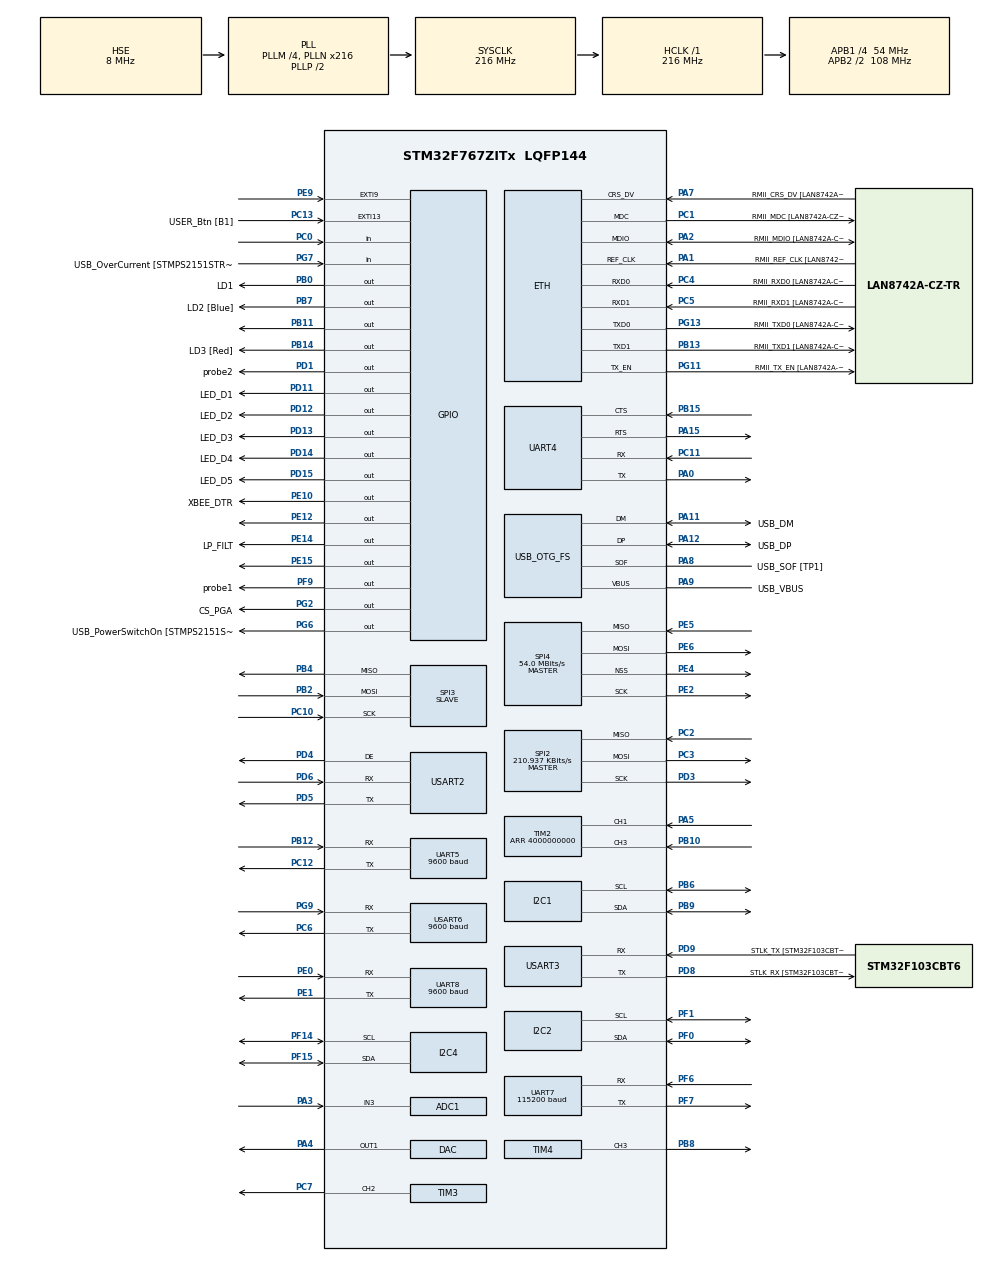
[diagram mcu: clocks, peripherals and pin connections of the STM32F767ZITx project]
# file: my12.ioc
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ADC1.Channel-6\#ChannelRegularConversion=ADC_CHANNEL_3
ADC1.ClockPrescaler=ADC_CLOCK_SYNC_PCLK_DIV4
ADC1.ContinuousConvMode=ENABLE
ADC1.DMAAccessMode=ADC_DMAACCESSMODE_2
ADC1.DMAContinuousRequests=ENABLE
ADC1.DataAlign=ADC_DATAALIGN_RIGHT
ADC1.DiscontinuousConvMode=DISABLE
ADC1.EOCSelection=ADC_EOC_SEQ_CONV
ADC1.EnableAnalogWatchDog=false
ADC1.ExternalTrigConv=ADC_SOFTWARE_START
ADC1.ExternalTrigConvEdge=ADC_EXTERNALTRIGCONVEDGE_NONE
ADC1.InjNumberOfConversion=0
ADC1.Mode=ADC_TRIPLEMODE_INTERL
ADC1.NbrOfConversion=1
ADC1.NbrOfConversionFlag=1
ADC1.Rank-6\#ChannelRegularConversion=1
ADC1.Resolution=ADC_RESOLUTION_12B
ADC1.SamplingTime-6\#ChannelRegularConversion=ADC_SAMPLETIME_3CYCLES
ADC1.ScanConvMode=ADC_SCAN_DISABLE
ADC1.TwoSamplingDelay=ADC_TWOSAMPLINGDELAY_5CYCLES
ADC1.master=1
ADC2.Channel-22\#ChannelRegularConversion=ADC_CHANNEL_3
ADC2.Channel-26\#ChannelRegularConversion=ADC_CHANNEL_3
ADC2.ContinuousConvMode=ENABLE
ADC2.DMAAccessMode=ADC_DMAACCESSMODE_2
ADC2.DMAContinuousRequests=DISABLE
ADC2.DataAlign=ADC_DATAALIGN_RIGHT
ADC2.DiscontinuousConvMode=DISABLE
ADC2.EOCSelection=ADC_EOC_SEQ_CONV
ADC2.EnableAnalogWatchDog=false
ADC2.InjNumberOfConversion=0
ADC2.Mode=ADC_TRIPLEMODE_INTERL
ADC2.NbrOfConversion=1
ADC2.NbrOfConversionFlag=1
ADC2.Rank-22\#ChannelRegularConversion=1
ADC2.Rank-26\#ChannelRegularConversion=1
ADC2.Resolution=ADC_RESOLUTION_12B
ADC2.SamplingTime-22\#ChannelRegularConversion=ADC_SAMPLETIME_3CYCLES
ADC2.SamplingTime-26\#ChannelRegularConversion=ADC_SAMPLETIME_3CYCLES
ADC2.ScanConvMode=ADC_SCAN_DISABLE
ADC3.Channel-14\#ChannelRegularConversion=ADC_CHANNEL_3
ADC3.ContinuousConvMode=ENABLE
ADC3.DMAAccessMode=ADC_DMAACCESSMODE_2
ADC3.DMAContinuousRequests=DISABLE
ADC3.DataAlign=ADC_DATAALIGN_RIGHT
ADC3.DiscontinuousConvMode=DISABLE
ADC3.EOCSelection=ADC_EOC_SEQ_CONV
ADC3.EnableAnalogWatchDog=false
ADC3.InjNumberOfConversion=0
ADC3.Mode=ADC_TRIPLEMODE_INTERL
ADC3.NbrOfConversion=1
ADC3.NbrOfConversionFlag=1
ADC3.Rank-14\#ChannelRegularConversion=1
ADC3.Resolution=ADC_RESOLUTION_12B
ADC3.SamplingTime-14\#ChannelRegularConversion=ADC_SAMPLETIME_3CYCLES
ADC3.ScanConvMode=ADC_SCAN_DISABLE
CORTEX_M7.CPU_DCache=Disabled
CORTEX_M7.CPU_ICache=Enabled
CORTEX_M7.PREFETCH_ENABLE=1
DAC.DAC_Trigger=DAC_TRIGGER_T7_TRGO
Dma.ADC1.2.Direction=DMA_PERIPH_TO_MEMORY
Dma.ADC1.2.FIFOMode=DMA_FIFOMODE_ENABLE
Dma.ADC1.2.FIFOThreshold=DMA_FIFO_THRESHOLD_FULL
Dma.ADC1.2.Instance=DMA2_Stream4
Dma.ADC1.2.MemBurst=DMA_MBURST_INC4
Dma.ADC1.2.MemDataAlignment=DMA_MDATAALIGN_WORD
Dma.ADC1.2.MemInc=DMA_MINC_ENABLE
Dma.ADC1.2.Mode=DMA_CIRCULAR
Dma.ADC1.2.PeriphBurst=DMA_PBURST_SINGLE
Dma.ADC1.2.PeriphDataAlignment=DMA_PDATAALIGN_HALFWORD
Dma.ADC1.2.PeriphInc=DMA_PINC_DISABLE
Dma.ADC1.2.Priority=DMA_PRIORITY_HIGH
Dma.DAC1.0.Direction=DMA_MEMORY_TO_PERIPH
Dma.DAC1.0.FIFOMode=DMA_FIFOMODE_ENABLE
Dma.DAC1.0.FIFOThreshold=DMA_FIFO_THRESHOLD_3QUARTERSFULL
Dma.DAC1.0.Instance=DMA1_Stream5
Dma.DAC1.0.MemBurst=DMA_MBURST_INC4
Dma.DAC1.0.MemDataAlignment=DMA_MDATAALIGN_BYTE
Dma.DAC1.0.MemInc=DMA_MINC_ENABLE
Dma.DAC1.0.Mode=DMA_NORMAL
Dma.DAC1.0.PeriphBurst=DMA_PBURST_SINGLE
Dma.DAC1.0.PeriphDataAlignment=DMA_PDATAALIGN_BYTE
Dma.DAC1.0.PeriphInc=DMA_PINC_DISABLE
Dma.DAC1.0.Priority=DMA_PRIORITY_LOW
Dma.Request0=DAC1
Dma.Request1=USART6_RX
Dma.Request2=ADC1
Dma.Request3=TIM2_UP/CH3
Dma.Request4=UART5_RX
Dma.Request5=UART5_TX
Dma.Request6=UART8_RX
Dma.Request7=USART6_TX
Dma.TIM2_UP/CH3.3.Direction=DMA_PERIPH_TO_MEMORY
Dma.TIM2_UP/CH3.3.FIFOMode=DMA_FIFOMODE_DISABLE
Dma.TIM2_UP/CH3.3.Instance=DMA1_Stream1
Dma.TIM2_UP/CH3.3.MemDataAlignment=DMA_MDATAALIGN_WORD
Dma.TIM2_UP/CH3.3.MemInc=DMA_MINC_ENABLE
Dma.TIM2_UP/CH3.3.Mode=DMA_CIRCULAR
Dma.TIM2_UP/CH3.3.PeriphDataAlignment=DMA_PDATAALIGN_WORD
Dma.TIM2_UP/CH3.3.PeriphInc=DMA_PINC_DISABLE
Dma.TIM2_UP/CH3.3.Priority=DMA_PRIORITY_LOW
Dma.UART5_RX.4.Direction=DMA_PERIPH_TO_MEMORY
Dma.UART5_RX.4.FIFOMode=DMA_FIFOMODE_DISABLE
Dma.UART5_RX.4.Instance=DMA1_Stream0
Dma.UART5_RX.4.MemDataAlignment=DMA_MDATAALIGN_BYTE
Dma.UART5_RX.4.MemInc=DMA_MINC_ENABLE
Dma.UART5_RX.4.Mode=DMA_CIRCULAR
Dma.UART5_RX.4.PeriphDataAlignment=DMA_PDATAALIGN_BYTE
Dma.UART5_RX.4.PeriphInc=DMA_PINC_DISABLE
Dma.UART5_RX.4.Priority=DMA_PRIORITY_LOW
Dma.UART5_TX.5.Direction=DMA_MEMORY_TO_PERIPH
Dma.UART5_TX.5.FIFOMode=DMA_FIFOMODE_DISABLE
Dma.UART5_TX.5.Instance=DMA1_Stream7
Dma.UART5_TX.5.MemDataAlignment=DMA_MDATAALIGN_BYTE
Dma.UART5_TX.5.MemInc=DMA_MINC_ENABLE
Dma.UART5_TX.5.Mode=DMA_NORMAL
Dma.UART5_TX.5.PeriphDataAlignment=DMA_PDATAALIGN_BYTE
Dma.UART5_TX.5.PeriphInc=DMA_PINC_DISABLE
Dma.UART5_TX.5.Priority=DMA_PRIORITY_LOW
Dma.UART8_RX.6.Direction=DMA_PERIPH_TO_MEMORY
Dma.UART8_RX.6.FIFOMode=DMA_FIFOMODE_DISABLE
Dma.UART8_RX.6.Instance=DMA1_Stream6
Dma.UART8_RX.6.MemDataAlignment=DMA_MDATAALIGN_BYTE
Dma.UART8_RX.6.MemInc=DMA_MINC_ENABLE
Dma.UART8_RX.6.Mode=DMA_CIRCULAR
Dma.UART8_RX.6.PeriphDataAlignment=DMA_PDATAALIGN_BYTE
Dma.UART8_RX.6.PeriphInc=DMA_PINC_DISABLE
Dma.UART8_RX.6.Priority=DMA_PRIORITY_MEDIUM
Dma.USART6_RX.1.Direction=DMA_PERIPH_TO_MEMORY
Dma.USART6_RX.1.FIFOMode=DMA_FIFOMODE_DISABLE
Dma.USART6_RX.1.Instance=DMA2_Stream1
Dma.USART6_RX.1.MemDataAlignment=DMA_MDATAALIGN_BYTE
Dma.USART6_RX.1.MemInc=DMA_MINC_ENABLE
Dma.USART6_RX.1.Mode=DMA_CIRCULAR
Dma.USART6_RX.1.PeriphDataAlignment=DMA_PDATAALIGN_BYTE
Dma.USART6_RX.1.PeriphInc=DMA_PINC_DISABLE
Dma.USART6_RX.1.Priority=DMA_PRIORITY_MEDIUM
Dma.USART6_TX.7.Direction=DMA_MEMORY_TO_PERIPH
Dma.USART6_TX.7.FIFOMode=DMA_FIFOMODE_ENABLE
Dma.USART6_TX.7.FIFOThreshold=DMA_FIFO_THRESHOLD_FULL
Dma.USART6_TX.7.Instance=DMA2_Stream6
Dma.USART6_TX.7.MemBurst=DMA_MBURST_INC4
Dma.USART6_TX.7.MemDataAlignment=DMA_MDATAALIGN_BYTE
Dma.USART6_TX.7.MemInc=DMA_MINC_ENABLE
Dma.USART6_TX.7.Mode=DMA_NORMAL
Dma.USART6_TX.7.PeriphBurst=DMA_PBURST_SINGLE
Dma.USART6_TX.7.PeriphDataAlignment=DMA_PDATAALIGN_BYTE
Dma.USART6_TX.7.PeriphInc=DMA_PINC_DISABLE
Dma.USART6_TX.7.Priority=DMA_PRIORITY_MEDIUM
ETH.ChecksumMode=ETH_CHECKSUM_BY_SOFTWARE
ETH.MACAddr=00\:80\:E1\:00\:AA\:02
ETH.MediaInterface=ETH_MEDIA_INTERFACE_RMII
ETH.PhyAddress=0
FREERTOS.BinarySemaphores01=ssicontent,Dynamic,NULL
FREERTOS.INCLUDE_vTaskCleanUpResources=1
FREERTOS.INCLUDE_vTaskDelayUntil=1
FREERTOS.INCLUDE_xQueueGetMutexHolder=1
FREERTOS.INCLUDE_xSemaphoreGetMutexHolder=1
FREERTOS.INCLUDE_xTimerPendFunctionCall=1
FREERTOS.Mutexes01=myMutex01,Dynamic,NULL
FREERTOS.Queues01=myQueue01,256,uint16_t,0,Dynamic,NULL,NULL
FREERTOS.Tasks01=defaultTask,0,2048,StartDefaultTask,Default,NULL,Dynamic,NULL,NULL;LPTask,-2,2048,StarLPTask,Default,NULL,Dynamic,NULL,NULL
FREERTOS.Timers01=myTimer01,Callback01,osTimerPeriodic,Default,NULL,Dynamic,NULL
FREERTOS.configCHECK_FOR_STACK_OVERFLOW=1
FREERTOS.configLIBRARY_MAX_SYSCALL_INTERRUPT_PRIORITY=3
FREERTOS.configMINIMAL_STACK_SIZE=0x100
FREERTOS.configTOTAL_HEAP_SIZE=0x18000
FREERTOS.configUSE_IDLE_HOOK=1
FREERTOS.configUSE_MALLOC_FAILED_HOOK=1
FREERTOS.configUSE_NEWLIB_REENTRANT=1
FREERTOS.configUSE_TIMERS=1
I2C1.Timing=0x20404768
I2C2.Timing=0x20404768
I2C4.Timing=0x20404768
IWDG.Prescaler=IWDG_PRESCALER_256
LWIP.ARP_QUEUEING=1
LWIP.ARP_QUEUE_LEN=32
LWIP.ARP_TABLE_SIZE=32
LWIP.CHECKSUM_BY_HARDWARE=1
LWIP.CHECKSUM_CHECK_ICMP=1
LWIP.CHECKSUM_CHECK_TCP=1
LWIP.CHECKSUM_GEN_ICMP=1
LWIP.CHECKSUM_GEN_IP=1
LWIP.CHECKSUM_GEN_TCP=1
LWIP.CHECKSUM_GEN_UDP=0
LWIP.HTTPD_USE_CUSTOM_FSDATA=1
LWIP.IP_DEBUG=LWIP_DBG_OFF
LWIP.LWIP_ALLOW_MEM_FREE_FROM_OTHER_CONTEXT=1
LWIP.LWIP_CHECKSUM_CTRL_PER_NETIF=0
LWIP.LWIP_CHECKSUM_ON_COPY=0
LWIP.LWIP_DBG_MIN_LEVEL=LWIP_DBG_LEVEL_WARNING
LWIP.LWIP_DBG_TYPES_ON=LWIP_DBG_OFF
LWIP.LWIP_DHCP_CHECK_LINK_UP=1
LWIP.LWIP_DISABLE_MEMP_SANITY_CHECKS=0
LWIP.LWIP_DNS=1
LWIP.LWIP_HTTPD=1
LWIP.LWIP_HTTPD_ABORT_ON_CLOSE_MEM_ERROR=1
LWIP.LWIP_HTTPD_CGI_SSI=1
LWIP.LWIP_HTTPD_DYNAMIC_HEADERS=0
LWIP.LWIP_HTTPD_MAX_TAG_INSERT_LEN=254
LWIP.LWIP_HTTPD_SSI=1
LWIP.LWIP_HTTPD_SSI_INCLUDE_TAG=0
LWIP.LWIP_HTTPD_SSI_RAW=0
LWIP.LWIP_HTTPD_SUPPORT_11_KEEPALIVE=1
LWIP.LWIP_HTTPD_SUPPORT_EXTSTATUS=1
LWIP.LWIP_HTTPD_SUPPORT_POST=1
LWIP.LWIP_NETIF_LINK_CALLBACK=1
LWIP.LWIP_NETIF_STATUS_CALLBACK=1
LWIP.LWIP_RAW=1
LWIP.LWIP_SO_LINGER=1
LWIP.LWIP_SO_RCVTIMEO=1
LWIP.LWIP_STATS=0
LWIP.LWIP_TCPIP_CORE_LOCKING=1
LWIP.LWIP_TCPIP_CORE_LOCKING_INPUT=0
LWIP.LWIP_TCPIP_TIMEOUT=1
LWIP.LWIP_TCP_CLOSE_TIMEOUT_MS_DEFAULT=20000
LWIP.MEMP_DEBUG=LWIP_DBG_OFF
LWIP.MEMP_NUM_PBUF=24
LWIP.MEMP_NUM_RAW_PCB=8
LWIP.MEMP_NUM_TCP_PCB=64
LWIP.MEMP_NUM_TCP_PCB_LISTEN=16
LWIP.MEMP_NUM_TCP_SEG=32
LWIP.MEMP_NUM_UDP_PCB=4
LWIP.MEMP_OVERFLOW_CHECK=2
LWIP.MEMP_SANITY_CHECK=1
LWIP.MEM_DEBUG=LWIP_DBG_OFF
LWIP.MEM_OVERFLOW_CHECK=2
LWIP.MEM_SANITY_CHECK=1
LWIP.MEM_SIZE=10000
LWIP.PBUF_DEBUG=LWIP_DBG_OFF
LWIP.PBUF_POOL_SIZE=42
LWIP.RAW_DEBUG=LWIP_DBG_OFF
LWIP.RECV_BUFSIZE_DEFAULT=20000
LWIP.SYS_DEBUG=LWIP_DBG_OFF
LWIP.SYS_LIGHTWEIGHT_PROT=0
LWIP.UDP_DEBUG=LWIP_DBG_OFF
LWIP.Version=v2.1.2_Cube
Mcu.Family=STM32F7
Mcu.Name=STM32F767ZITx
Mcu.Package=LQFP144
NVIC.ADC_IRQn=true\:6\:0\:true\:true\:true\:3\:false\:true\:true\:true
NVIC.DMA1_Stream0_IRQn=true\:3\:0\:false\:false\:true\:true\:false\:true\:true
NVIC.DMA1_Stream1_IRQn=true\:6\:0\:true\:false\:true\:false\:false\:true\:true
NVIC.DMA1_Stream5_IRQn=true\:6\:0\:true\:false\:true\:false\:false\:true\:true
NVIC.DMA1_Stream6_IRQn=true\:3\:0\:false\:false\:true\:true\:false\:true\:true
NVIC.DMA1_Stream7_IRQn=true\:3\:0\:false\:false\:true\:true\:false\:true\:true
NVIC.DMA2_Stream1_IRQn=true\:6\:0\:true\:false\:true\:false\:false\:true\:true
NVIC.DMA2_Stream4_IRQn=true\:2\:0\:true\:false\:true\:false\:false\:true\:true
NVIC.DMA2_Stream6_IRQn=true\:3\:0\:false\:false\:true\:true\:false\:true\:true
NVIC.ETH_IRQn=true\:6\:0\:true\:false\:true\:false\:true\:true\:true
NVIC.EXTI15_10_IRQn=true\:6\:0\:true\:true\:true\:4\:false\:true\:true\:true
NVIC.FPU_IRQn=true\:6\:0\:true\:false\:true\:false\:false\:false\:true
NVIC.OTG_FS_IRQn=true\:6\:0\:true\:false\:true\:false\:true\:true\:true
NVIC.PriorityGroup=NVIC_PRIORITYGROUP_4
NVIC.RCC_IRQn=true\:6\:0\:true\:false\:true\:false\:false\:false\:true
NVIC.TIM2_IRQn=true\:6\:0\:true\:false\:true\:false\:true\:true\:true
NVIC.TIM3_IRQn=true\:6\:0\:true\:false\:true\:false\:true\:true\:true
NVIC.TIM5_IRQn=true\:5\:0\:true\:false\:true\:false\:true\:true\:true
NVIC.TIM6_DAC_IRQn=true\:6\:0\:true\:false\:true\:false\:true\:true\:true
NVIC.TIM8_BRK_TIM12_IRQn=true\:0\:0\:false\:false\:true\:false\:true\:true\:true
NVIC.TIM8_TRG_COM_TIM14_IRQn=true\:1\:0\:true\:true\:true\:5\:false\:true\:true\:true
NVIC.TimeBase=TIM8_BRK_TIM12_IRQn
NVIC.TimeBaseIP=TIM12
NVIC.UART5_IRQn=true\:7\:0\:true\:false\:true\:false\:true\:true\:true
NVIC.UART8_IRQn=true\:3\:0\:false\:false\:true\:true\:true\:true\:true
NVIC.USART2_IRQn=true\:7\:0\:true\:true\:true\:1\:false\:true\:true\:true
NVIC.USART6_IRQn=true\:6\:0\:true\:true\:true\:2\:false\:true\:true\:true
PA0/WKUP.Mode=Asynchronous
PA0/WKUP.Signal=UART4_TX
PA1.GPIO_Label=RMII_REF_CLK [LAN8742A-CZ-TR_REFCLK0]
PA1.Mode=RMII
PA1.Signal=ETH_REF_CLK
PA10.Signal=MDIOS_MDIO
PA11.GPIO_Label=USB_DM
PA11.Mode=Device_Only
PA11.Signal=USB_OTG_FS_DM
PA12.GPIO_Label=USB_DP
PA12.Mode=Device_Only
PA12.Signal=USB_OTG_FS_DP
PA13.GPIO_Label=TMS
PA13.Mode=Serial_Wire
PA13.Signal=SYS_JTMS-SWDIO
PA14.GPIO_Label=TCK
PA14.Mode=Serial_Wire
PA14.Signal=SYS_JTCK-SWCLK
PA15.Mode=CTS_RTS
PA15.Signal=UART4_RTS
PA2.GPIO_Label=RMII_MDIO [LAN8742A-CZ-TR_MDIO]
PA2.Mode=RMII
PA2.Signal=ETH_MDIO
PA3.Signal=ADCx_IN3
PA4.Signal=COMP_DAC1_group
PA5.Signal=S_TIM2_CH1_ETR
PA7.GPIO_Label=RMII_CRS_DV [LAN8742A-CZ-TR_CRS_DV]
PA7.Mode=RMII
PA7.Signal=ETH_CRS_DV
PA8.GPIO_Label=USB_SOF [TP1]
PA8.Mode=Activate_SOF_FS
PA8.Signal=USB_OTG_FS_SOF
PA9.GPIO_Label=USB_VBUS
PA9.Mode=Activate_VBUS
PA9.Signal=USB_OTG_FS_VBUS
PB0.GPIO_Label=LD1
PB0.Signal=GPIO_Output
PB10.Signal=S_TIM2_CH3
PB11.Signal=GPIO_Output
PB12.Mode=Asynchronous
PB12.Signal=UART5_RX
PB13.GPIO_Label=RMII_TXD1 [LAN8742A-CZ-TR_TXD1]
PB13.Mode=RMII
PB13.Signal=ETH_TXD1
PB14.GPIO_Label=LD3 [Red]
PB14.Signal=GPIO_Output
PB15.Mode=CTS_RTS
PB15.Signal=UART4_CTS
PB2.Mode=Full_Duplex_Slave
PB2.Signal=SPI3_MOSI
PB3.GPIO_Label=SWO
PB3.Signal=SYS_JTDO-SWO
PB4.Mode=Full_Duplex_Slave
PB4.Signal=SPI3_MISO
PB6.GPIO_Pu=GPIO_PULLUP
PB6.Mode=I2C
PB6.Signal=I2C1_SCL
PB7.GPIO_Label=LD2 [Blue]
PB7.Signal=GPIO_Output
PB8.Signal=S_TIM4_CH3
PB9.GPIO_Pu=GPIO_PULLUP
PB9.Mode=I2C
PB9.Signal=I2C1_SDA
PC0.GPIO_PuPd=GPIO_PULLUP
PC0.Signal=GPIO_Input
PC1.GPIO_Label=RMII_MDC [LAN8742A-CZ-TR_MDC]
PC1.Mode=RMII
PC1.Signal=ETH_MDC
PC10.Mode=Full_Duplex_Slave
PC10.Signal=SPI3_SCK
PC11.Mode=Asynchronous
PC11.Signal=UART4_RX
PC12.GPIO_PuPd=GPIO_PULLUP
PC12.GPIO_Speed=GPIO_SPEED_FREQ_HIGH
PC12.Mode=Asynchronous
PC12.Signal=UART5_TX
PC13.GPIO_Label=USER_Btn [B1]
PC13.Signal=GPXTI13
PC14/OSC32_IN.Mode=LSE-External-Oscillator
PC14/OSC32_IN.Signal=RCC_OSC32_IN
PC15/OSC32_OUT.Mode=LSE-External-Oscillator
PC15/OSC32_OUT.Signal=RCC_OSC32_OUT
PC2.GPIO_Speed=GPIO_SPEED_FREQ_MEDIUM
PC2.Mode=Full_Duplex_Master
PC2.Signal=SPI2_MISO
PC3.GPIO_Speed=GPIO_SPEED_FREQ_MEDIUM
PC3.Mode=Full_Duplex_Master
PC3.Signal=SPI2_MOSI
PC4.GPIO_Label=RMII_RXD0 [LAN8742A-CZ-TR_RXD0]
PC4.Mode=RMII
PC4.Signal=ETH_RXD0
PC5.GPIO_Label=RMII_RXD1 [LAN8742A-CZ-TR_RXD1]
PC5.Mode=RMII
PC5.Signal=ETH_RXD1
PC6.GPIO_PuPd=GPIO_NOPULL
PC6.GPIO_Speed=GPIO_SPEED_FREQ_LOW
PC6.Mode=Asynchronous
PC6.Signal=USART6_TX
PC7.Signal=S_TIM3_CH2
PD1.GPIO_Label=probe2
PD1.GPIO_PuPd=GPIO_PULLUP
PD1.GPIO_Speed=GPIO_SPEED_FREQ_HIGH
PD1.Signal=GPIO_Output
PD11.GPIO_Label=LED_D1
PD11.PinState=GPIO_PIN_SET
PD11.Signal=GPIO_Output
PD12.GPIO_Label=LED_D2
PD12.PinState=GPIO_PIN_SET
PD12.Signal=GPIO_Output
PD13.GPIO_Label=LED_D3
PD13.PinState=GPIO_PIN_SET
PD13.Signal=GPIO_Output
PD14.GPIO_Label=LED_D4
PD14.PinState=GPIO_PIN_SET
PD14.Signal=GPIO_Output
PD15.GPIO_Label=LED_D5
PD15.PinState=GPIO_PIN_SET
PD15.Signal=GPIO_Output
PD3.GPIO_Speed=GPIO_SPEED_FREQ_MEDIUM
PD3.Mode=Full_Duplex_Master
PD3.Signal=SPI2_SCK
PD4.Mode=Hardware Flow Control (RS485)
PD4.Signal=USART2_DE
PD5.Mode=Asynchronous
PD5.Signal=USART2_TX
PD6.Mode=Asynchronous
PD6.Signal=USART2_RX
PD8.GPIO_Label=STLK_RX [STM32F103CBT6_PA3]
PD8.Mode=Multiprocessor_communication
PD8.Signal=USART3_TX
PD9.GPIO_Label=STLK_TX [STM32F103CBT6_PA2]
PD9.Mode=Multiprocessor_communication
PD9.Signal=USART3_RX
PE0.GPIO_PuPd=GPIO_PULLUP
PE0.GPIO_Speed=GPIO_SPEED_FREQ_MEDIUM
PE0.Mode=Asynchronous
PE0.Signal=UART8_RX
PE1.GPIO_Speed=GPIO_SPEED_FREQ_HIGH
PE1.Mode=Asynchronous
PE1.Signal=UART8_TX
PE10.GPIO_Label=XBEE_DTR
PE10.Signal=GPIO_Output
PE12.Signal=GPIO_Output
PE14.GPIO_Label=LP_FILT
PE14.Signal=GPIO_Output
PE15.Signal=GPIO_Output
PE2.Mode=Full_Duplex_Master
PE2.Signal=SPI4_SCK
PE4.Mode=NSS_Signal_Hard_Output
PE4.Signal=SPI4_NSS
PE5.Mode=Full_Duplex_Master
PE5.Signal=SPI4_MISO
PE6.Mode=Full_Duplex_Master
PE6.Signal=SPI4_MOSI
PE9.Signal=GPXTI9
PF0.GPIO_Pu=GPIO_PULLUP
PF0.Mode=I2C
PF0.Signal=I2C2_SDA
PF1.GPIO_Pu=GPIO_PULLUP
PF1.Mode=I2C
PF1.Signal=I2C2_SCL
PF14.GPIO_Pu=GPIO_PULLUP
PF14.Mode=I2C
PF14.Signal=I2C4_SCL
PF15.GPIO_Pu=GPIO_PULLUP
PF15.Mode=I2C
PF15.Signal=I2C4_SDA
PF6.GPIO_Speed=GPIO_SPEED_FREQ_MEDIUM
PF6.Mode=Asynchronous
PF6.Signal=UART7_RX
PF7.GPIO_PuPd=GPIO_PULLUP
PF7.GPIO_Speed=GPIO_SPEED_FREQ_MEDIUM
PF7.Mode=Asynchronous
PF7.Signal=UART7_TX
PF9.GPIO_Label=probe1
PF9.GPIO_PuPd=GPIO_PULLUP
PF9.GPIO_Speed=GPIO_SPEED_FREQ_HIGH
PF9.Signal=GPIO_Output
PG11.GPIO_Label=RMII_TX_EN [LAN8742A-CZ-TR_TXEN]
PG11.Mode=RMII
PG11.Signal=ETH_TX_EN
PG13.GPIO_Label=RMII_TXD0 [LAN8742A-CZ-TR_TXD0]
PG13.Mode=RMII
PG13.Signal=ETH_TXD0
PG2.GPIO_Label=CS_PGA
PG2.Signal=GPIO_Output
PG6.GPIO_Label=USB_PowerSwitchOn [STMPS2151STR_EN]
PG6.Signal=GPIO_Output
PG7.GPIO_Label=USB_OverCurrent [STMPS2151STR_FAULT]
PG7.Signal=GPIO_Input
PG9.GPIO_Mode=GPIO_MODE_AF_PP
PG9.GPIO_PuPd=GPIO_PULLUP
PG9.GPIO_Speed=GPIO_SPEED_FREQ_LOW
PG9.Mode=Asynchronous
PG9.Signal=USART6_RX
PH0/OSC_IN.GPIO_Label=MCO [STM32F103CBT6_PA8]
PH0/OSC_IN.Mode=HSE-External-Oscillator
PH0/OSC_IN.Signal=RCC_OSC_IN
PH1/OSC_OUT.Mode=HSE-External-Oscillator
PH1/OSC_OUT.Signal=RCC_OSC_OUT
ProjectManager.HeapSize=0x16000
ProjectManager.StackSize=0x6800
ProjectManager.TargetToolchain=STM32CubeIDE
RCC.48MHZClocksFreq_Value=24000000
RCC.AHBFreq_Value=216000000
RCC.APB1CLKDivider=RCC_HCLK_DIV4
RCC.APB1Freq_Value=54000000
RCC.APB1TimFreq_Value=108000000
RCC.APB2CLKDivider=RCC_HCLK_DIV2
RCC.APB2Freq_Value=108000000
RCC.APB2TimFreq_Value=216000000
RCC.CortexFreq_Value=216000000
RCC.HCLKFreq_Value=216000000
RCC.HSE_VALUE=8000000
RCC.HSI_VALUE=16000000
RCC.PLL48CLockSelection=RCC_CLK48SOURCE_PLLSAIP
RCC.PLLM=4
RCC.PLLMUL=RCC_PLL_MUL9
RCC.PLLN=216
RCC.PLLQ=6
RCC.PLLSAIP=RCC_PLLSAIP_DIV8
RCC.PRESCALERUSB=RCC_USBCLKSOURCE_PLL_DIV1_5
RCC.SYSCLKFreq_VALUE=216000000
RCC.SYSCLKSource=RCC_SYSCLKSOURCE_PLLCLK
RCC.SYSCLKSourceVirtual=RCC_SYSCLKSOURCE_PLLCLK
RCC.USBFreq_Value=48000000
RCC.VCOOutputFreq_Value=432000000
SH.ADCx_IN3.0=ADC1_IN3,IN3
SH.ADCx_IN3.1=ADC3_IN3,IN3
SH.ADCx_IN3.2=ADC2_IN3,IN3
SH.COMP_DAC1_group.0=DAC_OUT1,DAC_OUT1
SH.S_TIM2_CH1_ETR.0=TIM2_CH1,TriggerSource_TI1FP1
SH.S_TIM2_CH1_ETR.1=TIM2_CH1,Input_Capture1_from_TI1
SH.S_TIM2_CH1_ETR.2=TIM2_CH1,Input_Capture2_from_TI1
SH.S_TIM2_CH3.0=TIM2_CH3,Input_Capture3_from_TI3
SH.S_TIM3_CH2.0=TIM3_CH2,PWM Generation2 CH2
SH.S_TIM4_CH3.0=TIM4_CH3,Output Compare3 CH3
SPI2.BaudRatePrescaler=SPI_BAUDRATEPRESCALER_256
SPI2.CalculateBaudRate=210.937 KBits/s
SPI2.DataSize=SPI_DATASIZE_16BIT
SPI2.Direction=SPI_DIRECTION_2LINES
SPI2.Mode=SPI_MODE_MASTER
SPI2.VirtualType=VM_MASTER
SPI3.Direction=SPI_DIRECTION_2LINES
SPI3.Mode=SPI_MODE_SLAVE
SPI3.VirtualType=VM_SLAVE
SPI4.CalculateBaudRate=54.0 MBits/s
SPI4.Direction=SPI_DIRECTION_2LINES
SPI4.Mode=SPI_MODE_MASTER
SPI4.VirtualNSS=VM_NSSHARD
SPI4.VirtualType=VM_MASTER
TIM14.AutoReloadPreload=TIM_AUTORELOAD_PRELOAD_ENABLE
TIM14.Period=10800
TIM2.AutoReloadPreload=TIM_AUTORELOAD_PRELOAD_DISABLE
TIM2.Channel-Input_Capture1_from_TI1=TIM_CHANNEL_1
TIM2.Channel-Input_Capture2_from_TI1=TIM_CHANNEL_2
TIM2.Channel-Input_Capture3_from_TI3=TIM_CHANNEL_3
TIM2.CounterMode=TIM_COUNTERMODE_UP
TIM2.Period=4000000000
TIM3.AutoReloadPreload=TIM_AUTORELOAD_PRELOAD_ENABLE
TIM3.Channel-PWM\ Generation2\ CH2=TIM_CHANNEL_2
TIM3.Period=10000
TIM3.Prescaler=10800
TIM3.Pulse-PWM\ Generation2\ CH2=10
TIM4.AutoReloadPreload=TIM_AUTORELOAD_PRELOAD_ENABLE
TIM4.Channel-Output\ Compare3\ CH3=TIM_CHANNEL_3
TIM4.ClockDivision=TIM_CLOCKDIVISION_DIV1
TIM4.OCMode_3=TIM_OCMODE_TOGGLE
TIM4.Period=1100
TIM4.Pulse-Output\ Compare3\ CH3=550
TIM4.TIM_MasterOutputTrigger=TIM_TRGO_OC1
TIM5.CounterMode=TIM_COUNTERMODE_DOWN
TIM5.Period=4
TIM6.AutoReloadPreload=TIM_AUTORELOAD_PRELOAD_ENABLE
TIM6.Period=10000
TIM6.Prescaler=10800
TIM6.TIM_MasterOutputTrigger=TIM_TRGO_ENABLE
TIM7.AutoReloadPreload=TIM_AUTORELOAD_PRELOAD_ENABLE
TIM7.Period=9600
TIM7.TIM_MasterOutputTrigger=TIM_TRGO_UPDATE
UART5.BaudRate=9600
UART7.BaudRate=115200
UART7.DMADisableonRxErrorParam=UART_ADVFEATURE_DMA_ENABLEONRXERROR
UART7.OverrunDisableParam=UART_ADVFEATURE_OVERRUN_DISABLE
UART8.BaudRate=9600
UART8.DMADisableonRxErrorParam=UART_ADVFEATURE_DMA_ENABLEONRXERROR
UART8.Mode=MODE_RX
UART8.OverrunDisableParam=UART_ADVFEATURE_OVERRUN_DISABLE
USART2.VirtualMode-Asynchronous=VM_ASYNC
USART2.VirtualMode-Hardware\ Flow\ Control\ (RS485)=VM_ASYNC
USART2.WordLength=WORDLENGTH_8B
USART3.VirtualMode-Multiprocessor_communication=VM_ASYNC
USART6.BaudRate=9600
USART6.DMADisableonRxErrorParam=ADVFEATURE_DMA_ENABLEONRXERROR
USART6.OverrunDisableParam=ADVFEATURE_OVERRUN_DISABLE
USART6.VirtualMode-Asynchronous=VM_ASYNC
USART6.WordLength=WORDLENGTH_8B
USB_DEVICE.CLASS_NAME_FS=CDC
USB_DEVICE.VirtualMode-CDC_FS=Cdc
USB_DEVICE.VirtualModeFS=Cdc_FS
USB_OTG_FS.VirtualMode=Device_Only
VP_CRC_VS_CRC.Mode=CRC_Activate
VP_FATFS_VS_Generic.Mode=User_defined
VP_FREERTOS_VS_CMSIS_V1.Mode=CMSIS_V1
VP_IWDG_VS_IWDG.Mode=IWDG_Activate
VP_LWIP_VS_Enabled.Mode=Enabled
VP_RNG_VS_RNG.Mode=RNG_Activate
VP_SYS_VS_tim12.Mode=TIM12
VP_TIM14_VS_ClockSourceINT.Mode=Enable_Timer
VP_TIM1_VS_ClockSourceINT.Mode=Internal
VP_TIM2_VS_ClockSourceINT.Mode=Internal
VP_TIM2_VS_ControllerModeReset.Mode=Reset Mode
VP_TIM3_VS_ClockSourceINT.Mode=Internal
VP_TIM4_VS_ClockSourceINT.Mode=Internal
VP_TIM5_VS_ClockSourceINT.Mode=Internal
VP_TIM6_VS_ClockSourceINT.Mode=Enable_Timer
VP_TIM7_VS_ClockSourceINT.Mode=Enable_Timer
VP_USB_DEVICE_VS_USB_DEVICE_CDC_FS.Mode=CDC_FS
board=NUCLEO-F767ZI

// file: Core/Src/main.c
/* USER CODE BEGIN Header */
/**
 ******************************************************************************
 * @file           : main.c
 * @brief          : Main program body
 ******************************************************************************
 * @attention
 *
 * <h2><center>&copy; Copyright (c) 2020 STMicroelectronics.
 * All rights reserved.</center></h2>
 *
 * This software component is licensed by ST under Ultimate Liberty license
 * SLA0044, the "License"; You may not use this file except in compliance with
 * the License. You may obtain a copy of the License at:
 *                             www.st.com/SLA0044
 *
 ******************************************************************************
 */
/* USER CODE END Header */
#include "main.h"
#include "cmsis_os.h"
#include "adc.h"
#include "crc.h"
#include "dac.h"
#include "dma.h"
#include "fatfs.h"
#include "i2c.h"
#include "iwdg.h"
#include "lwip.h"
#include "rng.h"
#include "spi.h"
#include "tim.h"
#include "usart.h"
#include "usb_device.h"
#include "gpio.h"

/* USER CODE BEGIN Includes */
#include <time.h>
#include <stdlib.h>
#include <stdio.h>
#include <string.h>
#include "netif.h"
#include "adcstream.h"
#include "neo7m.h"
#include "mydebug.h"
#include "ip4.h"
#include "lwip.h"
#include "lwipopts.h"
#include "lwip/prot/dhcp.h"

#include "udpstream.h"
#include "version.h"
#include "www.h"
#include "dhcp.h"
#include "splat1.h"
#include "lcd.h"
#include "eeprom.h"
#include <queue.h>

//#define netif_dhcp_data(netif) ((struct dhcp*)netif_get_client_data(netif, LWIP_NETIF_CLIENT_DATA_INDEX_DHCP))

/* USER CODE END Includes */

/* USER CODE BEGIN PD */
volatile unsigned long rtos_debug_timer = 0;		// freeRTOS debug

const unsigned char phaser_wav[] = /* { 128, 0, 255, 0, 255, 0, 255, 0, 255, 0, 255,128,128,0,255,128 }; */
{ 114, 89, 141, 101, 114, 127, 102, 127, 89, 127, 128, 113, 141, 101, 128, 113, 128, 127, 128, 127, 153, 113, 114, 140,
		141, 140, 153, 113, 114, 127, 128, 127, 153, 140, 141, 152, 128, 113, 128, 127, 141, 141, 128, 127, 128, 101,
		128, 152, 140, 114, 101, 128, 127, 128, 113, 114, 128, 114, 128, 127, 102, 113, 102, 127, 127, 114, 113, 102,
		113, 114, 141, 102, 89, 101, 114, 89, 102, 102, 88, 141, 114, 128, 128, 114, 102, 113, 114, 127, 141, 127, 114,
		152, 141, 128, 114, 141, 141, 140, 128, 127, 128, 165, 141, 140, 102, 88, 102, 101, 89, 152, 128, 113, 102, 102,
		113, 102, 127, 114, 128, 113, 141, 127, 128, 113, 140, 166, 127, 114, 127, 141, 113, 128, 127, 114, 140, 153,
		102, 101, 102, 141, 127, 89, 88, 114, 101, 141, 113, 141, 152, 114, 113, 128, 152, 102, 101, 114, 141, 113, 89,
		101, 128, 101, 128, 140, 76, 113, 141, 89, 101, 114, 114, 140, 89, 101, 114, 114, 127, 141, 101, 114, 141, 152,
		128, 101, 152, 166, 127, 141, 113, 128, 152, 76, 140, 114, 141, 102, 128, 128, 113, 114, 152, 128, 113, 153,
		128, 88, 102, 140, 64, 88, 141, 88, 89, 101, 166, 102, 88, 179, 49, 114, 140, 64, 141, 113, 152, 102, 140, 141,
		101, 140, 166, 101, 153, 128, 88, 128, 127, 102, 128, 113, 102, 192, 128, 114, 140, 192, 114, 127, 141, 101,
		141, 88, 166, 75, 140, 166, 49, 166, 64, 127, 114, 76, 165, 102, 140, 102, 113, 166, 63, 179, 76, 179, 49, 153,
		75, 141, 102, 140, 114, 101, 166, 63, 191, 76, 165, 114, 178, 102, 128, 166, 114, 153, 76, 192, 49, 166, 37,
		178, 38, 152, 88, 102, 127, 76, 101, 76, 153, 64, 152, 64, 140, 76, 152, 102, 152, 76, 178, 76, 178, 89, 165,
		89, 152, 89, 204, 64, 191, 141, 114, 127, 153, 101, 179, 75, 205, 89, 141, 114, 114, 152, 64, 140, 141, 102,
		191, 64, 191, 89, 102, 152, 50, 204, 50, 191, 50, 101, 166, 63, 179, 24, 179, 88, 114, 152, 102, 140, 64, 128,
		64, 179, 75, 76, 179, 25, 205, 76, 101, 141, 88, 192, 89, 89, 178, 38, 165, 114, 113, 179, 11, 179, 166, 24,
		166, 140, 64, 205, 88, 102, 140, 64, 141, 178, 89, 101, 166, 37, 179, 140, 37, 205, 191, 38, 178, 153, 63, 205,
		75, 114, 230, 64, 114, 216, 49, 76, 204, 50, 88, 217, 89, 113, 205, 75, 114, 165, 76, 127, 153, 37, 141, 216,
		50, 128, 191, 50, 128, 179, 89, 101, 179, 88, 113, 205, 88, 89, 204, 102, 49, 192, 140, 75, 141, 165, 102, 140,
		192, 89, 88, 179, 89, 63, 166, 102, 64, 166, 140, 76, 140, 141, 140, 192, 88, 37, 166, 191, 50, 49, 179, 166,
		24, 64, 191, 128, 49, 152, 179, 37, 50, 178, 166, 50, 50, 178, 179, 63, 50, 166, 165, 25, 63, 205, 152, 50, 113,
		192, 152, 25, 49, 179, 152, 25, 64, 178, 166, 63, 64, 204, 192, 37, 25, 192, 191, 38, 25, 165, 230, 88, 12, 127,
		216, 128, 24, 102, 229, 192, 75, 64, 178, 205, 75, 25, 166, 255, 140, 12, 75, 205, 216, 76, 38, 127, 192, 127,
		64, 128, 216, 179, 64, 63, 179, 204, 102, 50, 140, 243, 165, 25, 37, 153, 242, 178, 76, 49, 114, 165, 128, 63,
		64, 141, 165, 102, 49, 114, 216, 153, 37, 38, 165, 243, 152, 38, 24, 140, 217, 152, 25, 25, 127, 192, 128, 25,
		25, 140, 230, 178, 50, 25, 101, 217, 204, 102, 38, 75, 179, 243, 178, 64, 24, 128, 242, 217, 101, 12, 50, 166,
		217, 166, 75, 38, 88, 153, 152, 101, 38, 50, 140, 192, 127, 24, 0, 75, 192, 243, 178, 76, 0, 50, 165, 217, 165,
		63, 12, 63, 166, 229, 179, 75, 25, 89, 191, 243, 204, 89, 25, 50, 141, 230, 229, 153, 63, 38, 101, 205, 243,
		191, 89, 11, 38, 127, 230, 229, 153, 38, 0, 50, 152, 230, 204, 114, 37, 50, 113, 179, 192, 128, 38, 12, 75, 166,
		204, 179, 88, 12, 37, 128, 216, 230, 179, 113, 64, 63, 114, 152, 166, 127, 89, 63, 64, 101, 153, 165, 127, 89,
		63, 89, 101, 141, 153, 140, 102, 89, 113, 141, 166, 152, 141, 113, 76, 75, 114, 165, 192, 165, 102, 38, 24, 76,
		165, 217, 216, 153, 75, 38, 49, 114, 191, 217, 192, 140, 89, 75, 114, 179, 205, 166, 114, 63, 38, 63, 128, 191,
		205, 165, 101, 50, 24, 64, 140, 205, 205, 140, 64, 12, 25, 89, 165, 230, 229, 192, 113, 50, 24, 38, 101, 179,
		217, 204, 153, 88, 38, 37, 76, 153, 205, 216, 179, 101, 38, 25, 49, 102, 153, 191, 179, 141, 88, 63, 50, 75,
		102, 140, 179, 165, 141, 101, 76, 75, 102, 140, 179, 178, 166, 114, 75, 50, 63, 114, 178, 217, 216, 166, 101,
		50, 24, 38, 101, 166, 204, 217, 179, 127, 76, 37, 50, 88, 153, 205, 216, 179, 140, 76, 37, 38, 88, 153, 205,
		230, 191, 128, 63, 12, 11, 49, 114, 178, 205, 191, 153, 102, 49, 25, 37, 76, 141, 191, 205, 179, 140, 76, 25,
		24, 50, 101, 166, 204, 217, 191, 141, 75, 38, 24, 64, 127, 179, 230, 229, 191, 128, 75, 38, 38, 49, 102, 141,
		178, 192, 166, 127, 102, 75, 76, 102, 140, 179, 178, 166, 140, 102, 75, 76, 101, 141, 165, 192, 191, 179, 127,
		88, 50, 49, 76, 113, 166, 204, 217, 178, 128, 64, 11, 0, 24, 76, 127, 192, 230, 229, 205, 152, 102, 50, 24, 38,
		75, 114, 165, 192, 192, 178, 141, 101, 49, 25, 24, 50, 101, 153, 191, 205, 191, 166, 113, 76, 37, 38, 63, 102,
		152, 205, 217, 217, 178, 128, 75, 38, 25, 38, 63, 114, 165, 205, 217, 216, 192, 153, 101, 50, 24, 25, 63, 102,
		152, 192, 216, 217, 178, 141, 76, 37, 25, 24, 50, 101, 153, 192, 217, 217, 192, 152, 102, 49, 25, 24, 38, 76,
		127, 179, 217, 216, 205, 165, 114, 63, 25, 11, 25, 63, 114, 166, 204, 230, 217, 204, 166, 113, 64, 38, 37, 50,
		88, 128, 178, 204, 217, 204, 166, 128, 76, 25, 12, 24, 50, 101, 140, 192, 216, 217, 192, 165, 128, 75, 38, 24,
		25, 49, 76, 127, 166, 204, 217, 204, 179, 141, 101, 64, 49, 50, 63, 89, 113, 166, 191, 205, 204, 192, 152, 114,
		76, 50, 49, 64, 88, 128, 165, 192, 204, 192, 178, 153, 128, 101, 76, 64, 64, 75, 102, 127, 166, 178, 192, 178,
		153, 127, 89, 49, 38, 38, 49, 76, 101, 128, 152, 179, 191, 192, 178, 153, 128, 88, 76, 63, 50, 63, 76, 102, 127,
		153, 166, 165, 166, 152, 128, 114, 76, 63, 50, 38, 49, 76, 101, 141, 165, 192, 205, 204, 192, 165, 141, 101, 76,
		64, 49, 50, 76, 89, 127, 153, 191, 205, 204, 191, 179, 152, 114, 88, 76, 63, 50, 64, 75, 102, 127, 153, 166,
		166, 165, 153, 140, 128, 113, 89, 75, 76, 76, 88, 102, 113, 141, 153, 166, 179, 178, 166, 140, 114, 101, 76, 64,
		64, 63, 76, 89, 127, 153, 178, 192, 204, 192, 192, 165, 128, 101, 64, 50, 37, 37, 50, 75, 102, 127, 166, 192,
		204, 205, 192, 178, 153, 127, 102, 75, 50, 38, 24, 38, 63, 89, 114, 140, 179, 191, 217, 204, 192, 178, 153, 140,
		102, 75, 38, 24, 12, 24, 50, 75, 102, 140, 166, 191, 205, 204, 205, 179, 166, 141, 114, 89, 63, 50, 50, 50, 76,
		89, 114, 140, 166, 191, 205, 205, 205, 191, 179, 140, 114, 75, 50, 38, 24, 25, 49, 64, 88, 102, 140, 166, 178,
		192, 204, 205, 191, 166, 140, 114, 75, 49, 25, 24, 25, 37, 64, 89, 113, 141, 165, 192, 205, 216, 217, 204, 179,
		166, 127, 102, 75, 50, 38, 37, 38, 64, 88, 102, 127, 153, 178, 192, 204, 205, 205, 192, 165, 141, 113, 102, 75,
		64, 49, 50, 49, 76, 88, 114, 140, 166, 178, 205, 216, 205, 192, 165, 141, 113, 89, 63, 38, 24, 25, 25, 37, 50,
		75, 102, 127, 153, 165, 192, 204, 205, 204, 192, 165, 153, 127, 102, 76, 64, 50, 38, 38, 37, 50, 76, 101, 128,
		152, 166, 191, 204, 217, 205, 204, 192, 165, 141, 127, 102, 75, 50, 38, 37, 38, 37, 64, 75, 102, 127, 153, 178,
		192, 205, 204, 192, 191, 179, 165, 140, 128, 101, 89, 63, 50, 50, 38, 37, 50, 75, 89, 113, 141, 165, 179, 191,
		204, 205, 204, 192, 165, 153, 127, 114, 88, 76, 50, 37, 38, 37, 50, 76, 89, 101, 128, 152, 166, 191, 192, 205,
		204, 205, 191, 179, 152, 141, 114, 88, 76, 49, 38, 38, 37, 38, 50, 63, 89, 101, 128, 152, 179, 192, 192, 205,
		204, 192, 178, 166, 152, 141, 113, 102, 75, 64, 49, 38, 38, 38, 50, 50, 63, 89, 101, 128, 152, 166, 179, 191,
		192, 192, 178, 179, 166, 152, 128, 113, 89, 75, 63, 50, 49, 50, 63, 63, 76, 88, 102, 113, 141, 152, 166, 192,
		191, 192, 191, 192, 178, 179, 165, 153, 128, 113, 89, 76, 63, 64, 49, 64, 64, 75, 89, 102, 113, 128, 152, 166,
		179, 192, 191, 192, 178, 179, 165, 153, 140, 128, 101, 89, 75, 64, 63, 49, 50, 64, 63, 76, 88, 102, 114, 127,
		141, 165, 179, 191, 192, 192, 192, 178, 179, 165, 153, 140, 128, 101, 89, 75, 50, 49, 50, 37, 38, 50, 63, 76,
		75, 89, 113, 128, 140, 153, 165, 179, 191, 192, 192, 191, 179, 178, 166, 152, 128, 113, 102, 89, 63, 64, 49, 38,
		38, 50, 50, 63, 76, 88, 114, 127, 141, 152, 166, 178, 192, 191, 192, 204, 192, 178, 166, 152, 153, 127, 114,
		101, 89, 75, 64, 63, 50, 49, 50, 49, 64, 75, 89, 101, 114, 127, 153, 165, 166, 178, 192, 204, 192, 192, 192,
		178, 166, 152, 141, 127, 114, 101, 89, 75, 64, 50, 49, 50, 63, 64, 76, 76, 89, 102, 127, 141, 140, 153, 166,
		179, 178, 179, 178, 179, 179, 166, 152, 141, 127, 114, 102, 88, 76, 63, 64, 49, 50, 49, 64, 63, 76, 75, 89, 102,
		114, 127, 141, 152, 166, 179, 178, 192, 191, 192, 192, 191, 179, 178, 166, 152, 141, 128, 113, 102, 89, 76, 63,
		64, 49, 50 };

const unsigned int phaser_wav_len = 1792;
unsigned int circuitboardpcb;
unsigned int newbuild;	// the (later) firmware build number on the server

/* USER CODE END PD */

/* USER CODE BEGIN PV */
struct netif *netif, *netif2;
extern const ip4_addr_t *ipaddr;
uint32_t t1sec = 0;
extern uint32_t t2cap[1];
int main_init_done = 0;
int lptask_init_done = 0;
char trigtimestr[32] = { "No Triggers" };
char nowtimestr[32] = { "\"No Time\"" };
char pressstr[16] = { "0" };
char tempstr[10] = { "0" };
char snstr[164] = { "\"No S/N\"" };
char statstr[264] = { "\"No status\"" };
char gpsstr[64] = { "\"No GPS data\"" };
uint16_t agc = 1;	// agc enable > 0
uint32_t myip;
uint32_t uip;		// udp target
QueueHandle_t consolerxq;
unsigned char con_ch;	// console uart input char

//char snstr[4] = {"No"};
//char statstr[4] = {"No"};
/* USER CODE END PV */

void SystemClock_Config(void);
void PeriphCommonClock_Config(void);
void MX_FREERTOS_Init(void);
static void MX_NVIC_Init(void);

/* USER CODE BEGIN 0 */
int _write(int file, char *ptr, int len) {
	int DataIdx;

	if (file == 1) {
		for (DataIdx = 0; DataIdx < len; DataIdx++) {
			__io_putchar(*ptr++);
		}
	} else {
		for (DataIdx = 0; DataIdx < len; DataIdx++) {
			HAL_UART_Transmit(&huart5, (uint8_t*) *ptr++, 1, 10);
		}
	}
	return len;
}

#ifdef configGENERATE_RUN_TIME_STATS
void rtos_debug_timer_setup() {

	HAL_TIM_Base_Start_IT(&htim14);		// TIM14 used for RTOS profiling
}
#endif

/* USER CODE END 0 */

int main(void)
{

  /* Enable I-Cache---------------------------------------------------------*/
  SCB_EnableICache();

  /* MCU Configuration--------------------------------------------------------*/

  /* Reset of all peripherals, Initializes the Flash interface and the Systick. */
  HAL_Init();

  /* Configure the system clock */
  SystemClock_Config();

/* Configure the peripherals common clocks */
  PeriphCommonClock_Config();

  /* Initialize all configured peripherals */
  MX_GPIO_Init();
  MX_DMA_Init();
  MX_USART2_UART_Init();
  MX_ADC1_Init();
  MX_ADC2_Init();
  MX_ADC3_Init();
  MX_RNG_Init();
  MX_TIM6_Init();
  MX_TIM3_Init();
  MX_TIM7_Init();
  MX_TIM1_Init();
  MX_CRC_Init();
  MX_TIM2_Init();
  MX_USART6_UART_Init();
  MX_DAC_Init();
  MX_FATFS_Init();
  MX_I2C1_Init();
  MX_UART4_Init();
  MX_UART5_Init();
  MX_USART3_UART_Init();
  MX_SPI4_Init();
  MX_SPI3_Init();
  MX_SPI2_Init();
  MX_I2C4_Init();
  MX_I2C2_Init();
  MX_TIM4_Init();
  MX_IWDG_Init();
  MX_TIM14_Init();
  MX_TIM5_Init();
  MX_UART8_Init();
  MX_UART7_Init();

  /* Initialize interrupts */
  MX_NVIC_Init();

  /* Call init function for freertos objects (in freertos.c) */
  MX_FREERTOS_Init();

  /* Start scheduler */
  osKernelStart();

  /* We should never get here as control is now taken by the scheduler */
  /* Infinite loop */
	while (1) {

	}
}

void SystemClock_Config(void)
{
  RCC_OscInitTypeDef RCC_OscInitStruct = {0};
  RCC_ClkInitTypeDef RCC_ClkInitStruct = {0};

  /** Configure LSE Drive Capability
  */
  HAL_PWR_EnableBkUpAccess();

  /** Configure the main internal regulator output voltage
  */
  __HAL_RCC_PWR_CLK_ENABLE();
  __HAL_PWR_VOLTAGESCALING_CONFIG(PWR_REGULATOR_VOLTAGE_SCALE1);

  /** Initializes the RCC Oscillators according to the specified parameters
  * in the RCC_OscInitTypeDef structure.
  */
  RCC_OscInitStruct.OscillatorType = RCC_OSCILLATORTYPE_LSI|RCC_OSCILLATORTYPE_HSE;
  RCC_OscInitStruct.HSEState = RCC_HSE_ON;
  RCC_OscInitStruct.LSIState = RCC_LSI_ON;
  RCC_OscInitStruct.PLL.PLLState = RCC_PLL_ON;
  RCC_OscInitStruct.PLL.PLLSource = RCC_PLLSOURCE_HSE;
  RCC_OscInitStruct.PLL.PLLM = 4;
  RCC_OscInitStruct.PLL.PLLN = 216;
  RCC_OscInitStruct.PLL.PLLP = RCC_PLLP_DIV2;
  RCC_OscInitStruct.PLL.PLLQ = 6;
  RCC_OscInitStruct.PLL.PLLR = 2;
  if (HAL_RCC_OscConfig(&RCC_OscInitStruct) != HAL_OK)
  {
    Error_Handler();
  }

  /** Activate the Over-Drive mode
  */
  if (HAL_PWREx_EnableOverDrive() != HAL_OK)
  {
    Error_Handler();
  }

  /** Initializes the CPU, AHB and APB buses clocks
  */
  RCC_ClkInitStruct.ClockType = RCC_CLOCKTYPE_HCLK|RCC_CLOCKTYPE_SYSCLK
                              |RCC_CLOCKTYPE_PCLK1|RCC_CLOCKTYPE_PCLK2;
  RCC_ClkInitStruct.SYSCLKSource = RCC_SYSCLKSOURCE_PLLCLK;
  RCC_ClkInitStruct.AHBCLKDivider = RCC_SYSCLK_DIV1;
  RCC_ClkInitStruct.APB1CLKDivider = RCC_HCLK_DIV4;
  RCC_ClkInitStruct.APB2CLKDivider = RCC_HCLK_DIV2;

  if (HAL_RCC_ClockConfig(&RCC_ClkInitStruct, FLASH_LATENCY_7) != HAL_OK)
  {
    Error_Handler();
  }
}

void PeriphCommonClock_Config(void)
{
  RCC_PeriphCLKInitTypeDef PeriphClkInitStruct = {0};

  /** Initializes the peripherals clock
  */
  PeriphClkInitStruct.PeriphClockSelection = RCC_PERIPHCLK_CLK48;
  PeriphClkInitStruct.PLLSAI.PLLSAIN = 192;
  PeriphClkInitStruct.PLLSAI.PLLSAIR = 2;
  PeriphClkInitStruct.PLLSAI.PLLSAIQ = 2;
  PeriphClkInitStruct.PLLSAI.PLLSAIP = RCC_PLLSAIP_DIV8;
  PeriphClkInitStruct.PLLSAIDivQ = 1;
  PeriphClkInitStruct.PLLSAIDivR = RCC_PLLSAIDIVR_2;
  PeriphClkInitStruct.Clk48ClockSelection = RCC_CLK48SOURCE_PLLSAIP;
  if (HAL_RCCEx_PeriphCLKConfig(&PeriphClkInitStruct) != HAL_OK)
  {
    Error_Handler();
  }
}

/**
  * @brief NVIC Configuration.
  * @retval None
  */
static void MX_NVIC_Init(void)
{
  /* USART2_IRQn interrupt configuration */
  HAL_NVIC_SetPriority(USART2_IRQn, 7, 0);
  HAL_NVIC_EnableIRQ(USART2_IRQn);
  /* USART6_IRQn interrupt configuration */
  HAL_NVIC_SetPriority(USART6_IRQn, 6, 0);
  HAL_NVIC_EnableIRQ(USART6_IRQn);
  /* ADC_IRQn interrupt configuration */
  HAL_NVIC_SetPriority(ADC_IRQn, 6, 0);
  HAL_NVIC_EnableIRQ(ADC_IRQn);
  /* EXTI15_10_IRQn interrupt configuration */
  HAL_NVIC_SetPriority(EXTI15_10_IRQn, 6, 0);
  HAL_NVIC_EnableIRQ(EXTI15_10_IRQn);
  /* TIM8_TRG_COM_TIM14_IRQn interrupt configuration */
  HAL_NVIC_SetPriority(TIM8_TRG_COM_TIM14_IRQn, 1, 0);
  HAL_NVIC_EnableIRQ(TIM8_TRG_COM_TIM14_IRQn);
}

/* USER CODE BEGIN 4 */

// find the crc for the running firmware (printout needed for server)
crc_rom() {
	unsigned char *base;
	extern xcrc32(const unsigned char *buf, int len, unsigned int init);
	extern uint32_t __fini_array_end;
	extern uint32_t _edata, _sdata;

	uint32_t xinit = 0xffffffff;
	uint32_t length, romcrc;

	if ((unsigned long) MX_NVIC_Init < 0x8100000) {
		base = 0x8000000;
	} else {
		base = 0x8100000;
	}

	length = (uint32_t) &__fini_array_end - (uint32_t) base + ((uint32_t) &_edata - (uint32_t) &_sdata);
	romcrc = xcrc32(base, length, xinit);
	printf("XCRC=0x%08x, base=0x%08x, len=%d\n", romcrc, base, length);
}

err_leds(int why) {
	volatile int i;

	for (;;) {
		switch (why) {
		case 0:
			break;
		case 1:			// LAN disconnected
			HAL_GPIO_TogglePin(GPIOD, LED_D1_Pin);
			HAL_GPIO_TogglePin(GPIOD, LED_D2_Pin);
			break;
		case 2:			// GPS not found
			HAL_GPIO_TogglePin(GPIOD, LED_D1_Pin);
			HAL_GPIO_TogglePin(GPIOD, LED_D3_Pin);
			break;
		case 3:			// udp target not found
			HAL_GPIO_TogglePin(GPIOD, LED_D1_Pin);
			HAL_GPIO_TogglePin(GPIOD, LED_D4_Pin);
			break;
		case 4:			// system crash - task exited
			HAL_GPIO_TogglePin(GPIOD, LED_D2_Pin);
			HAL_GPIO_TogglePin(GPIOD, LED_D3_Pin);
			break;
		case 5:			// GPS stopped responding
			HAL_GPIO_TogglePin(GPIOD, LED_D2_Pin);
			HAL_GPIO_TogglePin(GPIOD, LED_D4_Pin);
			break;
		case 6:			// server commanded a reboot
			HAL_GPIO_TogglePin(GPIOD, LED_D3_Pin);
			HAL_GPIO_TogglePin(GPIOD, LED_D4_Pin);
			break;
		case 7:			// server lookup failed
			HAL_GPIO_TogglePin(GPIOD, LED_D4_Pin);
			HAL_GPIO_TogglePin(GPIOD, LED_D5_Pin);
			break;
		case 8:			// serial number and udp target lookup failed
			HAL_GPIO_TogglePin(GPIOD, LED_D5_Pin);
			HAL_GPIO_TogglePin(GPIOD, LED_D1_Pin);
			break;
		}
		for (i = 0; i < 3500000; i++)
			;
	}
}

void netif_status_callbk_fn(struct netif *netif) {

	printf("netif_status changed\n");
	/*	printf("netif: IP address of '%c%c' set to %"U16_F".%"U16_F".%"U16_F".%"U16_F"\n", netif->name[0],
	 netif->name[1], ip4_addr1_16(netif_ip4_addr(netif)), ip4_addr2_16(netif_ip4_addr(netif)),
	 ip4_addr3_16(netif_ip4_addr(netif)), ip4_addr4_16(netif_ip4_addr(netif)));
	 */

	/*	printf("netif: Gateway %"U16_F".%"U16_F".%"U16_F".%"U16_F"\n",
	 ip4_addr1_16(netif_ip4_gw(netif)),
	 ip4_addr2_16(netif_ip4_gw(netif)),
	 ip4_addr3_16(netif_ip4_gw(netif)),
	 ip4_addr4_16(netif_ip4_gw(netif)));
	 printf("netif: NetMask %"U16_F".%"U16_F".%"U16_F".%"U16_F"\n",
	 ip4_addr1_16(netif_ip4_netmask(netif)),
	 ip4_addr2_16(netif_ip4_netmask(netif)),
	 ip4_addr3_16(netif_ip4_netmask(netif)),
	 ip4_addr4_16(netif_ip4_netmask(netif)));
	 */
//	netif_set_addr(netif,netif_ip4_addr(netif),netif_ip4_gw(netif),netif_ip4_netmask(netif));
}

void netif_link_callbk_fn(struct netif *netif) {

	if (netif->flags & NETIF_FLAG_LINK_UP) {
		printf("netif_link UP, flags=0x%02x\n", netif->flags);
	} else {
		printf("netif_link DOWN, flags=0x%02x\n", netif->flags);
		if (!(netif_is_link_up(netif))) {
#ifndef TESTING
			printf("LAN interface appears disconnected, rebooting...\n");
			rebootme(1);
#endif
		}
	}
}

uint32_t movavg(uint32_t new) {
	static uint32_t data[16] = { 0, 0, 0, 0, 0, 0, 0, 0, 0, 0, 0, 0, 0, 0, 0, 0 };
	int i;
	uint32_t sum = 0;

	for (i = 0; i < 15; i++) {
		data[i] = data[i + 1];		// old data is low index
		sum += data[i];
	}
	data[15] = new;		// new data at the end
	sum += new;

	return (sum >> 4);
}

// dma for DAC finished callback
void HAL_DAC_ConvCpltCallbackCh1(DAC_HandleTypeDef *hdac) {
	HAL_DAC_Stop_DMA(hdac, DAC_CHANNEL_1);
}

void HAL_TIM_IC_CaptureCallback(TIM_HandleTypeDef *htim) { // every second 1 pps (on external signal)
	uint32_t diff;
	static uint32_t lastcap = 0;

	if (htim->Instance == TIM2) {
		rtseconds = (statuspkt.NavPvt.sec + 1) % 60; // assume we get here before serial comms updates gps seconds field

#ifdef SPLAT1
		if (!(ledsenabled)) {
			HAL_GPIO_WritePin(GPIOD, LED_D1_Pin, GPIO_PIN_RESET);
		} else
			HAL_GPIO_TogglePin(GPIOD, LED_D1_Pin);
#else
	HAL_GPIO_TogglePin(GPIOB, LD1_Pin);		// green led
#endif

//printf(":%d ",rtseconds);
//		statuspkt.epochsecs++;
//		neotime();
#if 0		// clktrim with non-resetting pps counter
				if (lastcap > t2cap[0]) {		// counter wrapped
					diff = 4000000000 /*UINT_MAX*/- lastcap + t2cap[0];
				} else {
					diff = t2cap[0] - lastcap;
				}
#else
		diff = lastcap;
#endif
		statuspkt.clktrim = movavg(diff);
		/*		printf("TIM2 IC Callback CCR3=%08x, [0]%08xu, [1]%08x diff=%u, clktrim=%08x",
		 htim->Instance->CCR3, t2cap[0], lastcap, diff, statuspkt.clktrim);
		 printf(" globaladcavg=%u\n",globaladcavg);
		 */
		lastcap = t2cap[0];			// dma has populated t2cap from Channel 3 trigger on Timer 2
	} else if (htim->Instance == TIM4) {
		printf("Timer4 callback\n");
	}

//	htim->Instance->SR = 0;		// cheat

	/* USER CODE END Callback 1 */
}

// try to figure out what PCB is connected to the STM
// PC0 and PF5
void getboardpcb() {
	if ((HAL_GPIO_ReadPin(GPIOC, GPIO_PIN_0) == GPIO_PIN_RESET)) {// floats high on SPLAT1, so this must be a lightningboard
//		circuitboardpcb = LIGHTNINGBOARD1;		// prototype
        circuitboardpcb = LIGHTNINGBOARD2;		// Rev 1A and Rev 1B		// compile time!
	} else {
		circuitboardpcb = SPLATBOARD1;		// assumed
	}
}

void setupnotify() {
	/* Store the handle of the calling task. */
	xTaskToNotify = xTaskGetCurrentTaskHandle();
}

void printaline(char *str) {
	printf("%s----------------------------------------------------------------------------\n", str);
}

/* USER CODE END 4 */

void HAL_TIM_PeriodElapsedCallback(TIM_HandleTypeDef *htim)
{
  /* USER CODE BEGIN Callback 0 */

#ifdef configGENERATE_RUN_TIME_STATS

	if (htim->Instance == TIM14) {				// TIM14 used for RTOS profiling
//		printf("T14 PeriodElapsedCallback\n");
		rtos_debug_timer++;
		return;
	}
#endif

	if (htim->Instance == TIM5) {// TIM5 interrupt is used as hook to run ADC_Conv_complete() at a lower IRQ  priority than dmacomplete

//		printf("T5\n");
		ADC_Conv_complete();			// It is a one-shot
		return;
	}

	if (htim->Instance == TIM2) {
		printf("T2P PeriodElapsedCallback %lu %lu\n", t2cap[0], statuspkt.clktrim);
		return;
	}
	if (htim->Instance == TIM3) {
		printf("T3 PeriodElapsedCallback\n");
		return;
	}

	if (htim->Instance == TIM6) { // 1 second (internally timed, not compensated by GPS)
//		printf("T6 PeriodElapsedCallback %u SR=%u\n", myfullcomplete, TIM6->SR);
		t1sec++;
		statuspkt.sysuptime++;
		if (netup)
			statuspkt.netuptime++;
		if (gpslocked) {
			statuspkt.gpsuptime++;
			/*	if (epochvalid == 0) */{
				statuspkt.epochsecs = calcepoch32();
				epochvalid = 1;
			}
		} else {
			statuspkt.gpsuptime = 0;	// gps uptime is zero
			statuspkt.epochsecs = 0;	// make epoch time obviously wrong
			epochvalid = 0;
		}
		return;
	}

  /* USER CODE END Callback 0 */
  if (htim->Instance == TIM12) {
    HAL_IncTick();
  }
  /* USER CODE BEGIN Callback 1 */
	else {
		printf("Unknown Timer Period Elapsed callback\n");
	}
  /* USER CODE END Callback 1 */
}

void Error_Handler(void)
{
  /* USER CODE BEGIN Error_Handler_Debug */
	/* User can add his own implementation to report the HAL error return state */
	while (1) {
		printf("HAL error (main.c 2343)\n");
	}
  /* USER CODE END Error_Handler_Debug */
}

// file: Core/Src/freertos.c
/* USER CODE BEGIN Header */
/**
 ******************************************************************************
 * File Name          : freertos.c
 * Description        : Code for freertos applications
 ******************************************************************************
 * @attention
 *
 * <h2><center>&copy; Copyright (c) 2020 STMicroelectronics.
 * All rights reserved.</center></h2>
 *
 * This software component is licensed by ST under Ultimate Liberty license
 * SLA0044, the "License"; You may not use this file except in compliance with
 * the License. You may obtain a copy of the License at:
 *                             www.st.com/SLA0044
 *
 ******************************************************************************
 */
/* USER CODE END Header */

#include "FreeRTOS.h"
#include "task.h"
#include "main.h"
#include "cmsis_os.h"

osThreadId defaultTaskHandle;
osThreadId LPTaskHandle;
osMessageQId myQueue01Handle;
osTimerId myTimer01Handle;
osMutexId myMutex01Handle;
osSemaphoreId ssicontentHandle;

void StartDefaultTask(void const * argument);
void StarLPTask(void const * argument);
void Callback01(void const * argument);

extern void MX_USB_DEVICE_Init(void);
extern void MX_LWIP_Init(void);
void MX_FREERTOS_Init(void); /* (MISRA C 2004 rule 8.1) */

/* GetIdleTaskMemory prototype (linked to static allocation support) */
void vApplicationGetIdleTaskMemory( StaticTask_t **ppxIdleTaskTCBBuffer, StackType_t **ppxIdleTaskStackBuffer, uint32_t *pulIdleTaskStackSize );

/* GetTimerTaskMemory prototype (linked to static allocation support) */
void vApplicationGetTimerTaskMemory( StaticTask_t **ppxTimerTaskTCBBuffer, StackType_t **ppxTimerTaskStackBuffer, uint32_t *pulTimerTaskStackSize );

/* Hook prototypes */
void vApplicationIdleHook(void);
void vApplicationStackOverflowHook(xTaskHandle xTask, signed char *pcTaskName);
void vApplicationMallocFailedHook(void);

/* USER CODE BEGIN 2 */
__weak void vApplicationIdleHook(void) {
	/* vApplicationIdleHook() will only be called if configUSE_IDLE_HOOK is set
	 to 1 in FreeRTOSConfig.h. It will be called on each iteration of the idle
	 task. It is essential that code added to this hook function never attempts
	 to block in any way (for example, call xQueueReceive() with a block time
	 specified, or call vTaskDelay()). If the application makes use of the
	 vTaskDelete() API function (as this demo application does) then it is also
	 important that vApplicationIdleHook() is permitted to return to its calling
	 function, because it is the responsibility of the idle task to clean up
	 memory allocated by the kernel to any task that has since been deleted. */
}
/* USER CODE END 2 */

/* USER CODE BEGIN 4 */
__weak void vApplicationStackOverflowHook(xTaskHandle xTask, signed char *pcTaskName) {
	/* Run time stack overflow checking is performed if
	 configCHECK_FOR_STACK_OVERFLOW is defined to 1 or 2. This hook function is
	 called if a stack overflow is detected. */
}
/* USER CODE END 4 */

/* USER CODE BEGIN 5 */
__weak void vApplicationMallocFailedHook(void) {
	/* vApplicationMallocFailedHook() will only be called if
	 configUSE_MALLOC_FAILED_HOOK is set to 1 in FreeRTOSConfig.h. It is a hook
	 function that will get called if a call to pvPortMalloc() fails.
	 pvPortMalloc() is called internally by the kernel whenever a task, queue,
	 timer or semaphore is created. It is also called by various parts of the
	 demo application. If heap_1.c or heap_2.c are used, then the size of the
	 heap available to pvPortMalloc() is defined by configTOTAL_HEAP_SIZE in
	 FreeRTOSConfig.h, and the xPortGetFreeHeapSize() API function can be used
	 to query the size of free heap space that remains (although it does not
	 provide information on how the remaining heap might be fragmented). */
}
/* USER CODE END 5 */

/* USER CODE BEGIN GET_IDLE_TASK_MEMORY */
static StaticTask_t xIdleTaskTCBBuffer;
static StackType_t xIdleStack[configMINIMAL_STACK_SIZE];

void vApplicationGetIdleTaskMemory( StaticTask_t **ppxIdleTaskTCBBuffer, StackType_t **ppxIdleTaskStackBuffer, uint32_t *pulIdleTaskStackSize )
{
  *ppxIdleTaskTCBBuffer = &xIdleTaskTCBBuffer;
  *ppxIdleTaskStackBuffer = &xIdleStack[0];
  *pulIdleTaskStackSize = configMINIMAL_STACK_SIZE;
  /* place for user code */
}
/* USER CODE END GET_IDLE_TASK_MEMORY */

/* USER CODE BEGIN GET_TIMER_TASK_MEMORY */
static StaticTask_t xTimerTaskTCBBuffer;
static StackType_t xTimerStack[configTIMER_TASK_STACK_DEPTH];

void vApplicationGetTimerTaskMemory( StaticTask_t **ppxTimerTaskTCBBuffer, StackType_t **ppxTimerTaskStackBuffer, uint32_t *pulTimerTaskStackSize )
{
  *ppxTimerTaskTCBBuffer = &xTimerTaskTCBBuffer;
  *ppxTimerTaskStackBuffer = &xTimerStack[0];
  *pulTimerTaskStackSize = configTIMER_TASK_STACK_DEPTH;
  /* place for user code */
}
/* USER CODE END GET_TIMER_TASK_MEMORY */

void MX_FREERTOS_Init(void) {
  /* Create the mutex(es) */
  /* definition and creation of myMutex01 */
  osMutexDef(myMutex01);
  myMutex01Handle = osMutexCreate(osMutex(myMutex01));

  /* Create the semaphores(s) */
  /* definition and creation of ssicontent */
  osSemaphoreDef(ssicontent);
  ssicontentHandle = osSemaphoreCreate(osSemaphore(ssicontent), 1);

  /* Create the timer(s) */
  /* definition and creation of myTimer01 */
  osTimerDef(myTimer01, Callback01);
  myTimer01Handle = osTimerCreate(osTimer(myTimer01), osTimerPeriodic, NULL);

  /* Create the queue(s) */
  /* definition and creation of myQueue01 */
  osMessageQDef(myQueue01, 256, uint16_t);
  myQueue01Handle = osMessageCreate(osMessageQ(myQueue01), NULL);

  /* Create the thread(s) */
  /* definition and creation of defaultTask */
  osThreadDef(defaultTask, StartDefaultTask, osPriorityNormal, 0, 2048);
  defaultTaskHandle = osThreadCreate(osThread(defaultTask), NULL);

  /* definition and creation of LPTask */
  osThreadDef(LPTask, StarLPTask, osPriorityLow, 0, 2048);
  LPTaskHandle = osThreadCreate(osThread(LPTask), NULL);

}

void StartDefaultTask(void const * argument)
{
  /* init code for USB_DEVICE */
  MX_USB_DEVICE_Init();

  /* init code for LWIP */
  MX_LWIP_Init();
  for(;;)
  {
    osDelay(1);
  }
}

void StarLPTask(void const * argument)
{
  for(;;)
  {
    osDelay(1);
  }
}

/* Callback01 function */
void Callback01(void const * argument)
{
}
